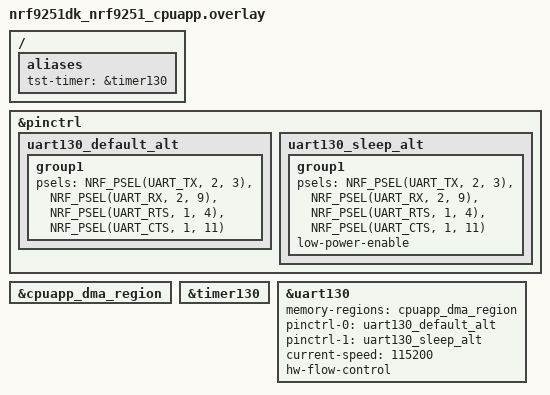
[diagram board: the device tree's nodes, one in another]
/*
 * Copyright (c) 2026 Nordic Semiconductor ASA
 *
 * SPDX-License-Identifier: LicenseRef-Nordic-5-Clause
 */

/ {
	aliases {
		tst-timer = &timer130;
	};
};

/* UART device used for test
 * not the default UART assignment for the LD
 */
&pinctrl {
	uart130_default_alt: uart130_default_alt {
		group1 {
			psels = <NRF_PSEL(UART_TX, 2, 3)>,
				<NRF_PSEL(UART_RX, 2, 9)>,
				<NRF_PSEL(UART_RTS, 1, 4)>,
				<NRF_PSEL(UART_CTS, 1, 11)>;
		};
	};

	uart130_sleep_alt: uart130_sleep_alt {
		group1 {
			psels = <NRF_PSEL(UART_TX, 2, 3)>,
				<NRF_PSEL(UART_RX, 2, 9)>,
				<NRF_PSEL(UART_RTS, 1, 4)>,
				<NRF_PSEL(UART_CTS, 1, 11)>;
			low-power-enable;
		};
	};
};

&cpuapp_dma_region {
	status = "okay";
};

&timer130 {
	status = "okay";
};

dut: &uart130 {
	status = "okay";
	memory-regions = <&cpuapp_dma_region>;
	pinctrl-0 = <&uart130_default_alt>;
	pinctrl-1 = <&uart130_sleep_alt>;
	pinctrl-names = "default", "sleep";
	current-speed = <115200>;
	hw-flow-control;
};
